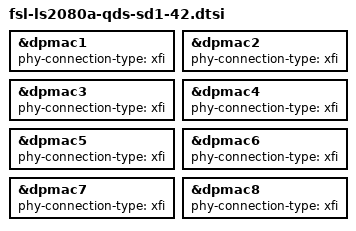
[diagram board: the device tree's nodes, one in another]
// SPDX-License-Identifier: GPL-2.0+ OR X11
/*
 * NXP LS2080aQDS device tree source for SERDES block #1 - protocol 42 (0x2a)
 *
 * Copyright 2020 NXP
 */

#include "fsl-ls2080a-qds.dtsi"

&dpmac1 {
	status = "okay";
	phy-connection-type = "xfi";
};

&dpmac2 {
	status = "okay";
	phy-connection-type = "xfi";
};

&dpmac3 {
	status = "okay";
	phy-connection-type = "xfi";
};

&dpmac4 {
	status = "okay";
	phy-connection-type = "xfi";
};

&dpmac5 {
	status = "okay";
	phy-connection-type = "xfi";
};

&dpmac6 {
	status = "okay";
	phy-connection-type = "xfi";
};

&dpmac7 {
	status = "okay";
	phy-connection-type = "xfi";
};

&dpmac8 {
	status = "okay";
	phy-connection-type = "xfi";
};
